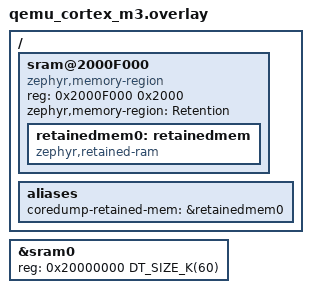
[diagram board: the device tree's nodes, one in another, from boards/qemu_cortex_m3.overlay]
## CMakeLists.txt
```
# SPDX-License-Identifier: Apache-2.0

cmake_minimum_required(VERSION 3.28.0)

find_package(Zephyr REQUIRED HINTS $ENV{ZEPHYR_BASE})
project(debug_coredump_backends)

target_sources(app PRIVATE src/main.c)

zephyr_library_sources_ifdef(
  CONFIG_DEBUG_COREDUMP_BACKEND_OTHER
  src/coredump_backend_empty.c
  )

target_sources_ifdef(
  CONFIG_DEBUG_COREDUMP_BACKEND_LOGGING_UDP
  app PRIVATE src/coredump_udp_receiver.c
  )
```

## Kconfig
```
# Copyright (c) 2023 Intel Corporation
#
# SPDX-License-Identifier: Apache-2.0

source "Kconfig.zephyr"

config TEST_STORED_COREDUMP
	bool "Expected backend has coredump storage."
	help
	  Set if the test expects coredump backend with storage.

config TEST_STORED_DUMP_SIZE
	int "Expected backend's coredump storage size."
	default 0
	help
	  Test expects coredump backend storage with the size given.
	  If zero, then it is ignored and not compared with the actual size.

config TEST_BACKEND_ERROR
	bool "Expect the backend to report an error"
	help
	  Set if the backend is expected to fail, e.g. because it is
	  misconfigured, and to report it through COREDUMP_QUERY_GET_ERROR.
```

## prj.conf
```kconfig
CONFIG_ZTEST=y
CONFIG_LOG=y
CONFIG_LOG_MODE_MINIMAL=y
CONFIG_DEBUG_COREDUMP=y
CONFIG_DEBUG_COREDUMP_BACKEND_LOGGING=y
CONFIG_MP_MAX_NUM_CPUS=1
CONFIG_DEBUG_COREDUMP_MEMORY_DUMP_MIN=y
CONFIG_DEBUG_COREDUMP_MEMORY_DUMP_LINKER_RAM=n
```

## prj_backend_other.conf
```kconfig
CONFIG_ZTEST=y
CONFIG_DEBUG_COREDUMP=y
CONFIG_DEBUG_COREDUMP_BACKEND_OTHER=y
CONFIG_MP_MAX_NUM_CPUS=1
CONFIG_DEBUG_COREDUMP_MEMORY_DUMP_MIN=y
CONFIG_DEBUG_COREDUMP_MEMORY_DUMP_LINKER_RAM=n
```

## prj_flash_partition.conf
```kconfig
CONFIG_ZTEST=y
CONFIG_LOG=y
CONFIG_LOG_MODE_MINIMAL=y
CONFIG_DEBUG_COREDUMP=y
CONFIG_DEBUG_COREDUMP_BACKEND_FLASH_PARTITION=y
CONFIG_MP_MAX_NUM_CPUS=1
CONFIG_FLASH=y
CONFIG_DEBUG_COREDUMP_MEMORY_DUMP_MIN=y
CONFIG_DEBUG_COREDUMP_MEMORY_DUMP_LINKER_RAM=n
```

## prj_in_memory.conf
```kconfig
CONFIG_ZTEST=y
CONFIG_LOG=y
CONFIG_LOG_MODE_MINIMAL=y
CONFIG_DEBUG_COREDUMP=y
CONFIG_DEBUG_COREDUMP_BACKEND_IN_MEMORY=y
CONFIG_DEBUG_COREDUMP_BACKEND_IN_MEMORY_SIZE=2048
CONFIG_DEBUG_COREDUMP_MEMORY_DUMP_MIN=y
```

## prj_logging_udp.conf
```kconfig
CONFIG_ZTEST=y
CONFIG_LOG=y
CONFIG_LOG_MODE_MINIMAL=y
CONFIG_DEBUG_COREDUMP=y
CONFIG_DEBUG_COREDUMP_BACKEND_LOGGING_UDP=y
CONFIG_DEBUG_COREDUMP_LOGGING_UDP_HOST="127.0.0.1:17777"
CONFIG_DEBUG_COREDUMP_LOGGING_UDP_MIRROR_TO_LOG=n
CONFIG_MP_MAX_NUM_CPUS=1
CONFIG_DEBUG_COREDUMP_MEMORY_DUMP_MIN=y

# Send the dump to a socket opened by the test itself, over loopback
CONFIG_NETWORKING=y
CONFIG_NET_IPV4=y
CONFIG_NET_IPV6=n
CONFIG_NET_UDP=y
CONFIG_NET_TCP=n
CONFIG_NET_SOCKETS=y
CONFIG_NET_LOOPBACK=y
CONFIG_NET_DRIVERS=y
CONFIG_NET_TEST=y
CONFIG_TEST_RANDOM_GENERATOR=y

# The whole dump is queued on the receiving socket before the test reads it
CONFIG_NET_PKT_RX_COUNT=32
CONFIG_NET_PKT_TX_COUNT=32
CONFIG_NET_BUF_RX_COUNT=256
CONFIG_NET_BUF_TX_COUNT=256
```

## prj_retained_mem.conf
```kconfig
CONFIG_ZTEST=y
CONFIG_ZTEST_NEW_API=y

CONFIG_DEBUG_COREDUMP=y
CONFIG_DEBUG_COREDUMP_BACKEND_RETAINED_MEM=y

CONFIG_RETAINED_MEM=y
CONFIG_RETAINED_MEM_CONCURRENT_ACCESS=n
```

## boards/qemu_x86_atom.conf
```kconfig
CONFIG_TEST_FLASH_DRIVERS=y
```

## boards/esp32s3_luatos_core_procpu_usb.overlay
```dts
/*
 * Copyright (c) 2023 Espressif Systems (Shanghai) Co., Ltd.
 *
 * SPDX-License-Identifier: Apache-2.0
 */

&flash0 {
	partitions {
		/*
		 * Reduce storage_partition to make space for
		 * coredump_partition
		 */

		storage_partition: partition@250000 {
			label = "storage";
			reg = <0x00250000 0x00005000>;
		};

		coredump_partition: partition@255000 {
			label = "coredump-partition";
			reg = <0x255000 DT_SIZE_K(4)>;
		};

	};
};
```

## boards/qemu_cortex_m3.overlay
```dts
#include <common/mem.h>

/ {
	sram@2000F000 {
		compatible = "zephyr,memory-region", "mmio-sram";
		reg = <0x2000F000 0x2000>;
		zephyr,memory-region = "Retention";
		status = "okay";

		retainedmem0: retainedmem {
			compatible = "zephyr,retained-ram";
			status = "okay";
        };
    };

	aliases {
		coredump-retained-mem = &retainedmem0;
	};
};

&sram0 {
	reg = <0x20000000 DT_SIZE_K(60)>;
};
```

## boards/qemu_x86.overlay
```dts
/*
 * Copyright (c) 2020 Intel Corporation
 *
 * SPDX-License-Identifier: Apache-2.0
 */

#include <mem.h>

&flash_sim0 {
	/*
	 * Sync with qemu_x86.dts on partitions to make sure
	 * size is large enough and there are no overlaps.
	 */

	partitions {
		coredump_partition: partition@31000 {

			reg = <0x31000 DT_SIZE_K(8)>;
			label = "coredump-partition";
		};
	};
};
```

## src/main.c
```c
/*
 * Copyright (c) 2012-2014 Wind River Systems, Inc.
 * Copyright (c) 2020-2023, Intel Corporation.
 *
 * SPDX-License-Identifier: Apache-2.0
 */

#include <zephyr/kernel.h>
#include <zephyr/sys/printk.h>

#include <zephyr/ztest.h>
#include <assert.h>
#include <zephyr/tc_util.h>

#include <zephyr/debug/coredump.h>

#define STACK_SIZE (1024 + CONFIG_TEST_EXTRA_STACK_SIZE)

static struct k_thread dump_thread;
static K_THREAD_STACK_DEFINE(dump_stack, STACK_SIZE);

void k_sys_fatal_error_handler(unsigned int reason, const struct arch_esf *pEsf)
{
	ARG_UNUSED(reason);
	ARG_UNUSED(pEsf);
}

void dump_entry(void *p1, void *p2, void *p3)
{
	unsigned int key;

	key = irq_lock();
	k_oops();
	TC_ERROR("SHOULD NEVER SEE THIS\n");
	irq_unlock(key);
}

void check_error(void)
{
	int ret;

	/* Check backend error if backend supports this query */
	ret = coredump_query(COREDUMP_QUERY_GET_ERROR, NULL);
	if (ret != -ENOTSUP) {
		if (IS_ENABLED(CONFIG_TEST_BACKEND_ERROR)) {
			zassert_not_equal(ret, 0, "Expected a backend error");
		} else {
			zassert_equal(ret, 0, "Error encountered! (%d)", ret);
		}
	}
}

void clear_error(void)
{
	int ret;

	/* Clear backend error if backend supports this query */
	ret = coredump_cmd(COREDUMP_CMD_CLEAR_ERROR, NULL);
	if (ret != -ENOTSUP) {
		zassert_equal(ret, 0, "Error encountered! (%d)", ret);
	}
}

static void *raise_coredump(void)
{
	k_tid_t tid;

	clear_error();

	/* Create a thread that crashes */
	tid = k_thread_create(&dump_thread, dump_stack,
			      K_THREAD_STACK_SIZEOF(dump_stack),
			      dump_entry, NULL, NULL, NULL,
			      0, 0, K_NO_WAIT);

	k_thread_join(tid, K_FOREVER);

	return &dump_thread;
}

void test_has_stored_dump(bool is_expected)
{
	int ret;

	/* Cannot proceed with previous errors */
	check_error();

	/* There should be a stored coredump now if backend has storage */
	ret = coredump_query(COREDUMP_QUERY_HAS_STORED_DUMP, NULL);
	if (ret == -ENOTSUP) {
#ifdef CONFIG_TEST_STORED_COREDUMP
		TC_ERROR("Can't query stored dump: unexpectedly not supported.\n");
		ztest_test_fail();
#else
		TC_PRINT("Can't query stored dump: expectedly not supported.\n");
		ztest_test_skip();
#endif
	} else if (ret == 1) {
#ifdef CONFIG_TEST_STORED_COREDUMP
		check_error();
		zassert_true(is_expected, "Unexpected coredump found.\n");
		ztest_test_pass();
#else
		TC_ERROR("Can't have a stored dump: not supported.\n");
		ztest_test_fail();
#endif
	} else if (ret == 0) {
#ifdef CONFIG_TEST_STORED_COREDUMP
		check_error();
		zassert_false(is_expected, "Should have stored dump!\n");
		ztest_test_pass();
#else
		TC_ERROR("Can't have an empty stored dump: not supported.\n");
		ztest_test_fail();
#endif
	} else {
		TC_ERROR("Error reading stored dump! (%d)\n", ret);
		ztest_test_fail();
	}
}

void test_verify_stored_dump(void)
{
	int ret;

	/* Cannot proceed with previous errors */
	check_error();

	/* There should be a stored coredump now if backend has storage */
	ret = coredump_cmd(COREDUMP_CMD_VERIFY_STORED_DUMP, NULL);
	if (ret == -ENOTSUP) {
#ifdef CONFIG_TEST_STORED_COREDUMP
		TC_ERROR("Can't verify stored dump: unexpectedly not supported.\n");
		ztest_test_fail();
#else
		TC_PRINT("Can't verify stored dump: expectedly not supported.\n");
		ztest_test_skip();
#endif
	} else if (ret == 1) {
#ifdef CONFIG_TEST_STORED_COREDUMP
		check_error();
		ztest_test_pass();
#else
		TC_ERROR("Can't have a stored dump: not supported.\n");
		ztest_test_fail();
#endif
	} else if (ret == 0) {
#ifdef CONFIG_TEST_STORED_COREDUMP
		TC_ERROR("Verification of stored dump failed!\n");
		ztest_test_fail();
#else
		TC_ERROR("Can't have a stored dump: not supported.\n");
		ztest_test_fail();
#endif
	} else {
		TC_ERROR("Error reading stored dump! (%d)\n", ret);
		ztest_test_fail();
	}
}

void test_invalidate_stored_dump(void)
{
	int ret;

	/* Cannot proceed with previous errors */
	check_error();

	/* There should be a stored coredump now if backend has storage */
	ret = coredump_cmd(COREDUMP_CMD_INVALIDATE_STORED_DUMP, NULL);
	if (ret == -ENOTSUP) {
#ifdef CONFIG_TEST_STORED_COREDUMP
		TC_ERROR("Can't invalidate stored dump: unexpectedly not supported.\n");
		ztest_test_fail();
#else
		TC_PRINT("Can't invalidate stored dump: expectedly not supported.\n");
		ztest_test_skip();
#endif
	} else if (ret == 0) {
#ifdef CONFIG_TEST_STORED_COREDUMP
		check_error();
		ztest_test_pass();
#else
		TC_ERROR("Can't invalidate the stored dump: not supported.\n");
		ztest_test_fail();
#endif
	} else {
		TC_ERROR("Error invalidating stored dump! (%d)\n", ret);
		ztest_test_fail();
	}
}

void test_erase_stored_dump(void)
{
	int ret;

	/* Cannot proceed with previous errors */
	check_error();

	/* There should be a stored coredump now if backend has storage */
	ret = coredump_cmd(COREDUMP_CMD_ERASE_STORED_DUMP, NULL);
	if (ret == -ENOTSUP) {
#ifdef CONFIG_TEST_STORED_COREDUMP
		TC_ERROR("Can't erase stored dump: unexpectedly not supported.\n");
		ztest_test_fail();
#else
		TC_PRINT("Can't erase stored dump: expectedly not supported.\n");
		ztest_test_skip();
#endif
	} else if (ret == 0) {
#ifdef CONFIG_TEST_STORED_COREDUMP
		check_error();
		ztest_test_pass();
#else
		TC_ERROR("Can't erase the stored dump: not supported.\n");
		ztest_test_fail();
#endif
	} else {
		TC_ERROR("Error erasing stored dump! (%d)\n", ret);
		ztest_test_fail();
	}
}

void test_get_stored_dump_size(int size_expected)
{
	int ret;

	/* Cannot proceed with previous errors */
	check_error();

	ret = coredump_query(COREDUMP_QUERY_GET_STORED_DUMP_SIZE, NULL);
	if (ret == -ENOTSUP) {
#ifdef CONFIG_TEST_STORED_COREDUMP
		TC_ERROR("Can't query stored dump size: unexpectedly not supported.\n");
		ztest_test_fail();
#else
		TC_PRINT("Can't query stored dump size: expectedly not supported.\n");
		ztest_test_skip();
#endif
	} else if (ret >= 0) {
#ifdef CONFIG_TEST_STORED_COREDUMP
		check_error();
		if (size_expected > 0) {
			zassert_equal(ret, size_expected,
				      "Coredump size %d != %d size expected.\n",
				      ret, size_expected);
		}
		ztest_test_pass();
#else
		TC_ERROR("Can't have a stored dump: not supported.\n");
		ztest_test_fail();
#endif
	} else {
		TC_ERROR("Error reading stored dump size! (%d)\n", ret);
		ztest_test_fail();
	}
}

#ifdef CONFIG_DEBUG_COREDUMP_BACKEND_IN_MEMORY
static int copy_stored_dump(off_t offset, uint8_t *buffer, size_t length)
{
	struct coredump_cmd_copy_arg copy = {
		.offset = offset,
		.buffer = buffer,
		.length = length,
	};

	return coredump_cmd(COREDUMP_CMD_COPY_STORED_DUMP, &copy);
}
#endif

/* Execute tests in exact sequence with the stored core dump. */

ZTEST(coredump_backends, test_coredump_0_ready) {
	check_error();
	ztest_test_pass();
}

ZTEST(coredump_backends, test_coredump_1_stored) {
	test_has_stored_dump(true);
}

ZTEST(coredump_backends, test_coredump_2_size) {
	test_get_stored_dump_size(CONFIG_TEST_STORED_DUMP_SIZE);
}

#ifdef CONFIG_DEBUG_COREDUMP_BACKEND_IN_MEMORY
ZTEST(coredump_backends, test_coredump_3_copy_bounds) {
	static uint8_t buf[CONFIG_DEBUG_COREDUMP_BACKEND_IN_MEMORY_SIZE + 1];
	const off_t size = CONFIG_DEBUG_COREDUMP_BACKEND_IN_MEMORY_SIZE;

	/* The whole dump area can be copied, but nothing past it */
	zassert_true(copy_stored_dump(0, buf, size) >= 0);
	zassert_true(copy_stored_dump(size - 1, buf, 1) >= 0);
	zassert_equal(copy_stored_dump(0, buf, size + 1), -EINVAL);
	zassert_equal(copy_stored_dump(size, buf, 1), -EINVAL);
	zassert_equal(copy_stored_dump(-1, buf, 1), -EINVAL);
	zassert_equal(copy_stored_dump(1, buf, SIZE_MAX), -EINVAL);
}
#endif

ZTEST(coredump_backends, test_coredump_3_verify) {
	test_verify_stored_dump();
}

ZTEST(coredump_backends, test_coredump_4_invalidate) {
	test_invalidate_stored_dump();
}

ZTEST(coredump_backends, test_coredump_5_erase) {
	test_erase_stored_dump();
}

ZTEST_SUITE(coredump_backends, NULL, raise_coredump, NULL, NULL, NULL);
```

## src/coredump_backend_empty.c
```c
/*
 * Copyright Meta Platforms, Inc. and its affiliates.
 *
 * SPDX-License-Identifier: Apache-2.0
 */

#include <errno.h>
#include <zephyr/debug/coredump.h>

static int error;
static bool is_valid;

static void coredump_empty_backend_start(void)
{
	/* Reset error, is_valid */
	error = 0;
	is_valid = false;
}

static void coredump_empty_backend_end(void)
{
	is_valid = true;
}

static void coredump_empty_backend_buffer_output(uint8_t *buf, size_t buflen)
{
	/* no-op */
}

static int coredump_empty_backend_query(enum coredump_query_id query_id,
					  void *arg)
{
	int ret;

	switch (query_id) {
	case COREDUMP_QUERY_GET_ERROR:
		ret = error;
		break;
	case COREDUMP_QUERY_HAS_STORED_DUMP:
		ret = 0;
		if (is_valid) {
			ret = 1;
		}
		break;
	case COREDUMP_QUERY_GET_STORED_DUMP_SIZE:
		ret = 0;
		break;
	default:
		ret = -ENOTSUP;
		break;
	}

	return ret;
}

static int coredump_empty_backend_cmd(enum coredump_cmd_id cmd_id,
					void *arg)
{
	int ret;

	switch (cmd_id) {
	case COREDUMP_CMD_CLEAR_ERROR:
		error = 0;
		ret = 0;
		break;
	case COREDUMP_CMD_VERIFY_STORED_DUMP:
		ret = 0;
		if (is_valid) {
			ret = 1;
		}
		break;
	case COREDUMP_CMD_INVALIDATE_STORED_DUMP:
		is_valid = false;
		ret = 0;
		break;
	case COREDUMP_CMD_ERASE_STORED_DUMP:
		is_valid = false;
		ret = 0;
		break;
	default:
		ret = -ENOTSUP;
		break;
	}

	return ret;
}

struct coredump_backend_api coredump_backend_other = {
	.start = coredump_empty_backend_start,
	.end = coredump_empty_backend_end,
	.buffer_output = coredump_empty_backend_buffer_output,
	.query = coredump_empty_backend_query,
	.cmd = coredump_empty_backend_cmd,
};
```

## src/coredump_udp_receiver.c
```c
/*
 * SPDX-FileCopyrightText: Copyright The Zephyr Project Contributors
 * SPDX-License-Identifier: Apache-2.0
 */

#include <string.h>

#include <zephyr/init.h>
#include <zephyr/net/socket.h>
#include <zephyr/sys/byteorder.h>
#include <zephyr/ztest.h>

#include <zephyr/debug/coredump.h>

/* Frame format of subsys/debug/coredump/coredump_backend_logging_udp.c */
#define ZCDU_HDR_SIZE    16U
#define ZCDU_MAX_PAYLOAD 1024U
#define ZCDU_FLAG_END    0x0001U
#define ZCDU_PORT        17777U

#define DUMP_BUF_SIZE 8192U
#define RX_TIMEOUT_MS 2000

static int rx_sock = -1;
static uint8_t dump[DUMP_BUF_SIZE];

/* Bind the backend's peer address before the test suite raises the coredump. */
static int coredump_udp_receiver_init(void)
{
	const char *host = CONFIG_DEBUG_COREDUMP_LOGGING_UDP_HOST;
	struct net_sockaddr_storage addr = {0};

	if (!net_ipaddr_parse(host, strlen(host), net_sad(&addr)) ||
	    net_port_set_default(net_sad(&addr), ZCDU_PORT) < 0) {
		return 0;
	}

	rx_sock = zsock_socket(addr.ss_family, NET_SOCK_DGRAM, NET_IPPROTO_UDP);
	if (rx_sock < 0) {
		return 0;
	}

	if (zsock_bind(rx_sock, net_sad(&addr), sizeof(addr)) < 0) {
		zsock_close(rx_sock);
		rx_sock = -1;
	}

	return 0;
}

SYS_INIT(coredump_udp_receiver_init, APPLICATION, CONFIG_APPLICATION_INIT_PRIORITY);

ZTEST(coredump_backends, test_coredump_6_udp_received)
{
	uint8_t frame[ZCDU_HDR_SIZE + ZCDU_MAX_PAYLOAD];
	const struct coredump_hdr_t *hdr = (const struct coredump_hdr_t *)dump;
	uint32_t expected_seq = 0U;
	size_t total = 0U;
	bool end = false;

	if (IS_ENABLED(CONFIG_TEST_BACKEND_ERROR)) {
		ztest_test_skip();
	}

	zassert_true(rx_sock >= 0, "Receiving socket not open");

	while (!end) {
		struct zsock_pollfd pfd = {
			.fd = rx_sock,
			.events = ZSOCK_POLLIN,
		};
		ssize_t len;
		uint32_t offset;
		uint16_t payload_len;
		uint16_t flags;

		zassert_equal(zsock_poll(&pfd, 1, RX_TIMEOUT_MS), 1,
			      "No frame received after %u frames", expected_seq);

		len = zsock_recv(rx_sock, frame, sizeof(frame), ZSOCK_MSG_DONTWAIT);
		zassert_true(len >= 0, "recv failed (errno %d)", errno);
		zassert_true(len >= ZCDU_HDR_SIZE, "Short frame (%d bytes)", (int)len);
		zassert_mem_equal(frame, "ZCDU", 4, "Bad frame magic");

		offset = sys_get_le32(&frame[4]);
		payload_len = sys_get_le16(&frame[8]);
		flags = sys_get_le16(&frame[10]);

		zassert_equal(sys_get_le32(&frame[12]), expected_seq, "Unexpected sequence number");
		zassert_equal(offset, total, "Unexpected stream offset");
		zassert_equal(len, ZCDU_HDR_SIZE + payload_len, "Frame length mismatch");
		zassert_true(total + payload_len <= sizeof(dump), "Coredump too large for test");

		memcpy(&dump[total], &frame[ZCDU_HDR_SIZE], payload_len);
		total += payload_len;
		expected_seq++;
		end = (flags & ZCDU_FLAG_END) != 0U;
	}

	zassert_true(total > sizeof(*hdr), "Coredump too short (%zu bytes)", total);
	zassert_equal(hdr->id[0], 'Z', "Bad coredump header");
	zassert_equal(hdr->id[1], 'E', "Bad coredump header");

	TC_PRINT("Received %zu coredump bytes in %u frames\n", total, expected_seq);
}
```
